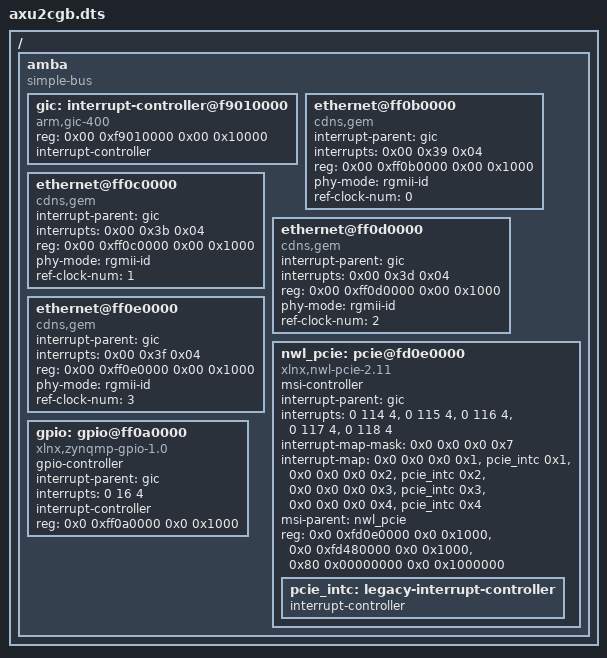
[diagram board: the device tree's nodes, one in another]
/* SPDX-License-Identifier: BSD-2-Clause */

/**
 * @file
 *
 * @ingroup RTEMSBSPsAArch64XilinxZynqMP
 *
 * @brief This file provides the base ZynqMP device tree
 */

/*
 * Copyright (C) 2022 On-Line Applications Research Corporation (OAR)
 * Written by Kinsey Moore <kinsey.moore@oarcorp.com>
 *
 * Redistribution and use in source and binary forms, with or without
 * modification, are permitted provided that the following conditions
 * are met:
 * 1. Redistributions of source code must retain the above copyright
 *    notice, this list of conditions and the following disclaimer.
 * 2. Redistributions in binary form must reproduce the above copyright
 *    notice, this list of conditions and the following disclaimer in the
 *    documentation and/or other materials provided with the distribution.
 *
 * THIS SOFTWARE IS PROVIDED BY THE COPYRIGHT HOLDERS AND CONTRIBUTORS "AS IS"
 * AND ANY EXPRESS OR IMPLIED WARRANTIES, INCLUDING, BUT NOT LIMITED TO, THE
 * IMPLIED WARRANTIES OF MERCHANTABILITY AND FITNESS FOR A PARTICULAR PURPOSE
 * ARE DISCLAIMED. IN NO EVENT SHALL THE COPYRIGHT OWNER OR CONTRIBUTORS BE
 * LIABLE FOR ANY DIRECT, INDIRECT, INCIDENTAL, SPECIAL, EXEMPLARY, OR
 * CONSEQUENTIAL DAMAGES (INCLUDING, BUT NOT LIMITED TO, PROCUREMENT OF
 * SUBSTITUTE GOODS OR SERVICES; LOSS OF USE, DATA, OR PROFITS; OR BUSINESS
 * INTERRUPTION) HOWEVER CAUSED AND ON ANY THEORY OF LIABILITY, WHETHER IN
 * CONTRACT, STRICT LIABILITY, OR TORT (INCLUDING NEGLIGENCE OR OTHERWISE)
 * ARISING IN ANY WAY OUT OF THE USE OF THIS SOFTWARE, EVEN IF ADVISED OF THE
 * POSSIBILITY OF SUCH DAMAGE.
 */

/dts-v1/;

/ {
	#address-cells = <0x02>;
	#size-cells = <0x02>;

	amba {
		compatible = "simple-bus";
		#address-cells = <0x02>;
		#size-cells = <0x02>;
		ranges;

		gic: interrupt-controller@f9010000 {
			compatible = "arm,gic-400";
			#address-cells = <0x02>;
			#interrupt-cells = <0x03>;
			reg = <0x00 0xf9010000 0x00 0x10000>;
			interrupt-controller;
		};

		ethernet@ff0b0000 {
			compatible = "cdns,gem";
			status = "okay";
			interrupt-parent = <&gic>;
			interrupts = <0x00 0x39 0x04>;
			reg = <0x00 0xff0b0000 0x00 0x1000>;
			phy-mode = "rgmii-id";
			ref-clock-num = <0>;
		};

		ethernet@ff0c0000 {
			compatible = "cdns,gem";
			status = "okay";
			interrupt-parent = <&gic>;
			interrupts = <0x00 0x3b 0x04>;
			reg = <0x00 0xff0c0000 0x00 0x1000>;
			phy-mode = "rgmii-id";
			ref-clock-num = <1>;
		};

		ethernet@ff0d0000 {
			compatible = "cdns,gem";
			status = "okay";
			interrupt-parent = <&gic>;
			interrupts = <0x00 0x3d 0x04>;
			reg = <0x00 0xff0d0000 0x00 0x1000>;
			phy-mode = "rgmii-id";
			ref-clock-num = <2>;
		};

		ethernet@ff0e0000 {
			compatible = "cdns,gem";
			status = "okay";
			interrupt-parent = <&gic>;
			interrupts = <0x00 0x3f 0x04>;
			reg = <0x00 0xff0e0000 0x00 0x1000>;
			phy-mode = "rgmii-id";
			ref-clock-num = <3>;
		};

		nwl_pcie: pcie@fd0e0000 {
			#address-cells = <3>;
			#size-cells = <2>;
			compatible = "xlnx,nwl-pcie-2.11";
			#interrupt-cells = <1>;
			msi-controller;
			device_type = "pci";
			interrupt-parent = <&gic>;
			interrupts = <0 114 4>, <0 115 4>, <0 116 4>, <0 117 4>, <0 118 4>;
			interrupt-names = "msi0", "msi1", "intx", "dummy", "misc";
			interrupt-map-mask = <0x0 0x0 0x0 0x7>;
			interrupt-map = <0x0 0x0 0x0 0x1 &pcie_intc 0x1>,
					<0x0 0x0 0x0 0x2 &pcie_intc 0x2>,
					<0x0 0x0 0x0 0x3 &pcie_intc 0x3>,
					<0x0 0x0 0x0 0x4 &pcie_intc 0x4>;

			msi-parent = <&nwl_pcie>;
			reg = <0x0 0xfd0e0000 0x0 0x1000>,
						<0x0 0xfd480000 0x0 0x1000>,
						<0x80 0x00000000 0x0 0x1000000>;
			reg-names = "breg", "pcireg", "cfg";
			ranges = <0x02000000 0x00000000 0xe0000000 0x00000000 0xe0000000 0x00000000 0x10000000  /* non-prefetchable memory */
					0x43000000 0x00000006 0x00000000 0x00000006 0x00000000 0x00000002 0x00000000>;/* prefetchable memory */

			pcie_intc: legacy-interrupt-controller {
				interrupt-controller;
				#address-cells = <0>;
				#interrupt-cells = <1>;
			};

		};

		gpio: gpio@ff0a0000 {
			compatible = "xlnx,zynqmp-gpio-1.0";
			status = "okay";
			#gpio-cells = <0x2>;
			gpio-controller;
			interrupt-parent = <&gic>;
			interrupts = <0 16 4>;
			interrupt-controller;
			#interrupt-cells = <2>;
			reg = <0x0 0xff0a0000 0x0 0x1000>;
			/* power-domains = <&zynqmp_firmware PD_GPIO>; */
		};

	};
};
